VERSION ""

NS_ :

BS_:

BU_: XXX

BO_ 539 CRZ_INFO: 8 XXX

BO_ 540 CRZ_CTRL: 8 XXX

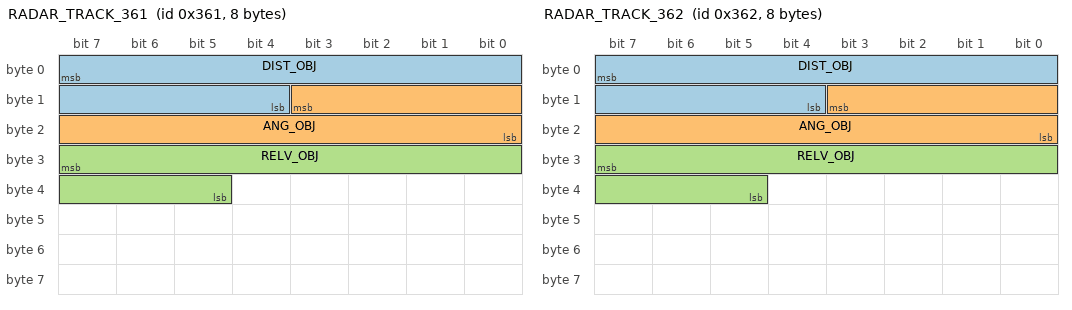
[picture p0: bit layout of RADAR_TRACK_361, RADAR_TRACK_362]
BO_ 865 RADAR_TRACK_361: 8 XXX
 SG_ DIST_OBJ : 7|12@0+ (1,0) [0|4095] "" XXX
 SG_ ANG_OBJ : 11|12@0- (1,0) [-2047|2047] "" XXX
 SG_ RELV_OBJ : 31|11@0- (1,0) [-1023|1023] "" XXX

BO_ 866 RADAR_TRACK_362: 8 XXX
 SG_ DIST_OBJ : 7|12@0+ (1,0) [0|4095] "" XXX
 SG_ ANG_OBJ : 11|12@0- (1,0) [-2047|2047] "" XXX
 SG_ RELV_OBJ : 31|11@0- (1,0) [-1023|1023] "" XXX

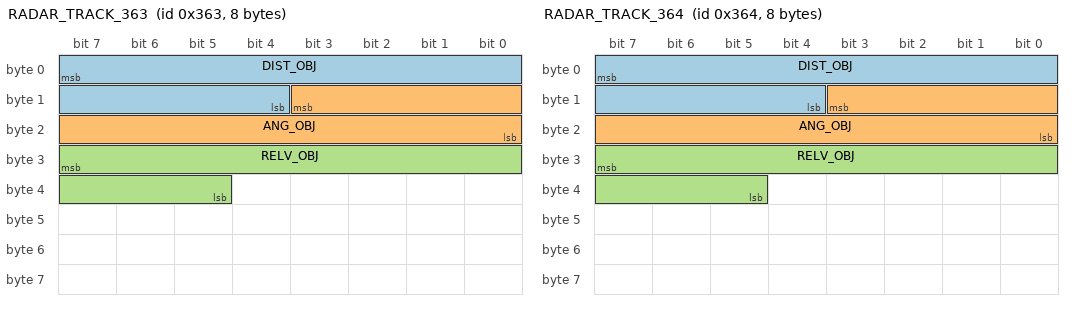
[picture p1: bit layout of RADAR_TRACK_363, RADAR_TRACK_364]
BO_ 867 RADAR_TRACK_363: 8 XXX
 SG_ DIST_OBJ : 7|12@0+ (1,0) [0|4095] "" XXX
 SG_ ANG_OBJ : 11|12@0- (1,0) [-2047|2047] "" XXX
 SG_ RELV_OBJ : 31|11@0- (1,0) [-1023|1023] "" XXX

BO_ 868 RADAR_TRACK_364: 8 XXX
 SG_ DIST_OBJ : 7|12@0+ (1,0) [0|4095] "" XXX
 SG_ ANG_OBJ : 11|12@0- (1,0) [-2047|2047] "" XXX
 SG_ RELV_OBJ : 31|11@0- (1,0) [-1023|1023] "" XXX

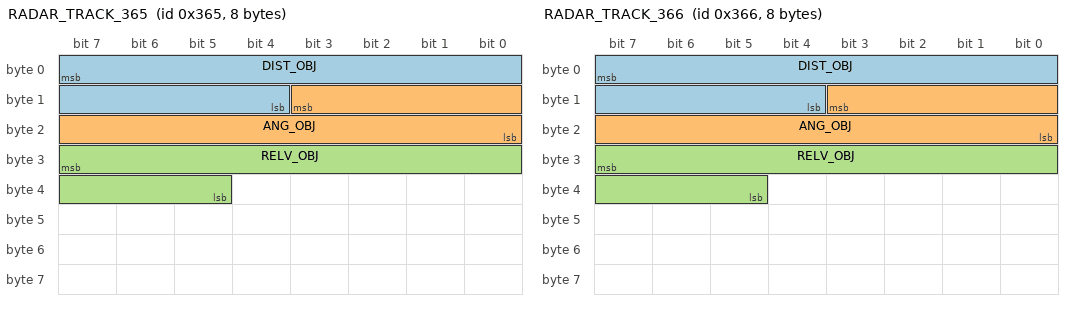
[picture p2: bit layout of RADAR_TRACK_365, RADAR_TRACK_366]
BO_ 869 RADAR_TRACK_365: 8 XXX
 SG_ DIST_OBJ : 7|12@0+ (1,0) [0|4095] "" XXX
 SG_ ANG_OBJ : 11|12@0- (1,0) [-2047|2047] "" XXX
 SG_ RELV_OBJ : 31|11@0- (1,0) [-1023|1023] "" XXX

BO_ 870 RADAR_TRACK_366: 8 XXX
 SG_ DIST_OBJ : 7|12@0+ (1,0) [0|4095] "" XXX
 SG_ ANG_OBJ : 11|12@0- (1,0) [-2047|2047] "" XXX
 SG_ RELV_OBJ : 31|11@0- (1,0) [-1023|1023] "" XXX

BO_ 1177 RADAR_499: 8 XXX
